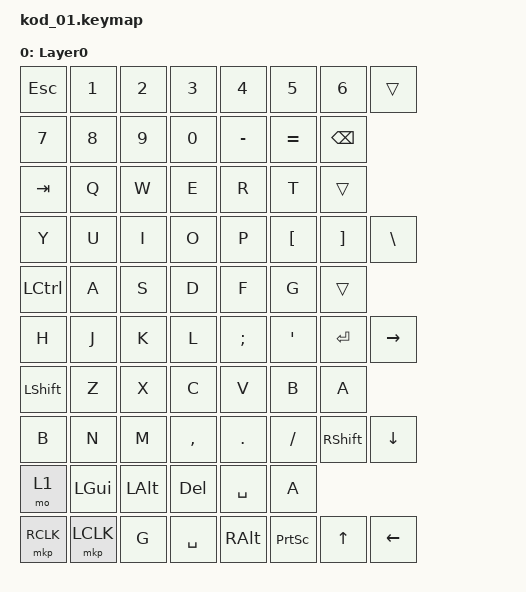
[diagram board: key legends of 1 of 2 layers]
/*
 * kod_01.keymap
 */

#include <behaviors.dtsi>
#include <dt-bindings/zmk/keys.h>
#include <dt-bindings/zmk/bt.h>

#define ZMK_POINTING_DEFAULT_SCRL_VAL 60

#include <dt-bindings/zmk/pointing.h>

/ {
    scroll_encoder: scroll_encoder {
        compatible = "zmk,behavior-sensor-rotate";
        #sensor-binding-cells = <0>;
        bindings = <&msc SCRL_DOWN>, <&msc SCRL_UP>;
        tap-ms = <60>;
    };

    keymap {
        compatible = "zmk,keymap";

        default_layer {
            display-name = "Layer0";
            bindings = <
                &kp ESC   &kp N1    &kp N2   &kp N3    &kp N4    &kp N5    &kp N6    &trans
                &kp N7    &kp N8    &kp N9   &kp N0    &kp MINUS &kp EQUAL &kp BSPC

                &kp TAB   &kp Q     &kp W    &kp E     &kp R     &kp T     &trans
                &kp Y     &kp U     &kp I    &kp O     &kp P     &kp LBKT  &kp RBKT  &kp BSLH

                &kp LCTRL &kp A     &kp S    &kp D     &kp F     &kp G     &trans
                &kp H     &kp J     &kp K    &kp L     &kp SEMI  &kp SQT   &kp RET   &kp RIGHT

                &kp LSHFT &kp Z     &kp X    &kp C     &kp V     &kp B     &kp A
                &kp B     &kp N     &kp M    &kp COMMA &kp DOT   &kp FSLH  &kp RSHFT &kp DOWN

                &mo 1     &kp LGUI  &kp LALT &kp DEL   &kp SPACE &kp A
                &mkp RCLK &mkp LCLK &kp G    &kp SPACE &kp RALT  &kp PSCRN &kp UP    &kp LEFT
            >;
            sensor-bindings = <&scroll_encoder>;
        };

        fn_layer {
            display-name = "Layer1";
            bindings = <
                /* 1段目: チルダ, F1-F12 */
                &kp GRAVE &kp F1    &kp F2   &kp F3    &kp F4
                &kp F5    &kp F6    &kp F7   &kp F8    &kp F9
                &kp F10   &kp F11   &kp F12  &trans    &trans

                /* 2段目: BT操作 */
                /* Fn+Q-T: BTプロファイル0-4選択 */
                /* Fn+Y: 全ボンドクリア */
                &trans        &bt BT_SEL 0  &bt BT_SEL 1  &bt BT_SEL 2  &bt BT_SEL 3  &bt BT_SEL 4  &trans
                &bt BT_CLR_ALL &trans       &trans        &trans        &trans        &trans        &trans    &trans

                /* 3段目 */
                &trans    &trans    &trans   &trans    &trans    &trans
                &trans    &trans    &trans   &trans    &trans    &trans    &trans    &trans

                /* 4段目 */
                &trans    &trans    &trans   &trans    &trans    &trans
                &trans    &trans    &trans   &trans    &trans    &trans    &trans    &trans

                /* 5段目 */
                &trans    &trans    &trans   &trans    &trans    &trans
                &trans    &trans    &trans   &trans    &trans    &trans
            >;
            sensor-bindings = <&inc_dec_kp C_VOL_UP C_VOL_DN>;
        };
    };
};
